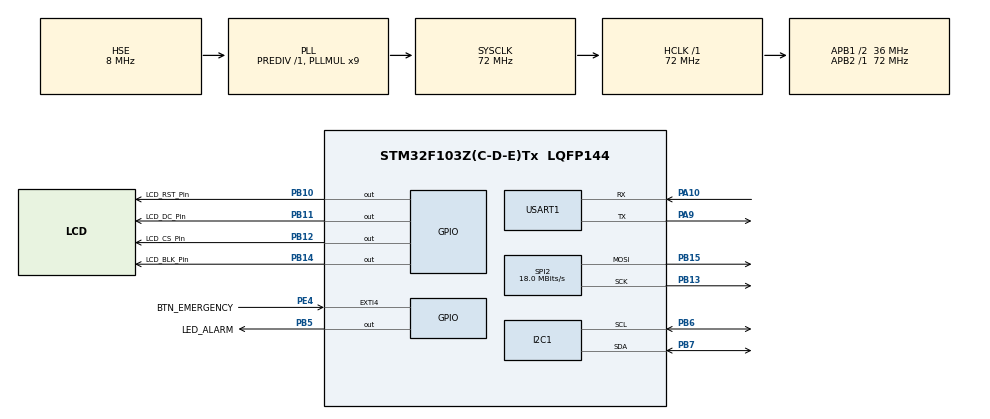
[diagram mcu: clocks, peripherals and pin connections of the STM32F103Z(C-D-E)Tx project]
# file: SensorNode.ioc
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Dma.Request0=USART1_RX
Dma.Request1=USART1_TX
Dma.USART1_RX.0.Direction=DMA_PERIPH_TO_MEMORY
Dma.USART1_RX.0.Instance=DMA1_Channel5
Dma.USART1_RX.0.MemDataAlignment=DMA_MDATAALIGN_BYTE
Dma.USART1_RX.0.MemInc=DMA_MINC_ENABLE
Dma.USART1_RX.0.Mode=DMA_CIRCULAR
Dma.USART1_RX.0.PeriphDataAlignment=DMA_PDATAALIGN_BYTE
Dma.USART1_RX.0.PeriphInc=DMA_PINC_DISABLE
Dma.USART1_RX.0.Priority=DMA_PRIORITY_MEDIUM
Dma.USART1_TX.1.Direction=DMA_MEMORY_TO_PERIPH
Dma.USART1_TX.1.Instance=DMA1_Channel4
Dma.USART1_TX.1.MemDataAlignment=DMA_MDATAALIGN_BYTE
Dma.USART1_TX.1.MemInc=DMA_MINC_ENABLE
Dma.USART1_TX.1.Mode=DMA_NORMAL
Dma.USART1_TX.1.PeriphDataAlignment=DMA_PDATAALIGN_BYTE
Dma.USART1_TX.1.PeriphInc=DMA_PINC_DISABLE
Dma.USART1_TX.1.Priority=DMA_PRIORITY_MEDIUM
Mcu.Family=STM32F1
Mcu.Name=STM32F103Z(C-D-E)Tx
Mcu.Package=LQFP144
NVIC.DMA1_Channel4_IRQn=true\:0\:0\:false\:false\:true\:false\:true\:true
NVIC.DMA1_Channel5_IRQn=true\:0\:0\:false\:false\:true\:false\:true\:true
NVIC.EXTI4_IRQn=true\:6\:0\:true\:false\:true\:true\:true\:true
NVIC.PriorityGroup=NVIC_PRIORITYGROUP_4
NVIC.TIM4_IRQn=true\:15\:0\:false\:false\:true\:false\:true\:true
NVIC.TimeBase=TIM4_IRQn
NVIC.TimeBaseIP=TIM4
NVIC.USART1_IRQn=true\:6\:0\:true\:false\:true\:true\:true\:true
OSC_IN.Mode=HSE-External-Oscillator
OSC_IN.Signal=RCC_OSC_IN
OSC_OUT.Mode=HSE-External-Oscillator
OSC_OUT.Signal=RCC_OSC_OUT
PA10.Mode=Asynchronous
PA10.Signal=USART1_RX
PA13.Mode=Serial_Wire
PA13.Signal=SYS_JTMS-SWDIO
PA14.Mode=Serial_Wire
PA14.Signal=SYS_JTCK-SWCLK
PA9.Mode=Asynchronous
PA9.Signal=USART1_TX
PB10.GPIO_Label=LCD_RST_Pin
PB10.PinState=GPIO_PIN_SET
PB10.Signal=GPIO_Output
PB11.GPIO_Label=LCD_DC_Pin
PB11.PinState=GPIO_PIN_SET
PB11.Signal=GPIO_Output
PB12.GPIO_Label=LCD_CS_Pin
PB12.PinState=GPIO_PIN_SET
PB12.Signal=GPIO_Output
PB13.Mode=TX_Only_Simplex_Unidirect_Master
PB13.Signal=SPI2_SCK
PB14.GPIO_Label=LCD_BLK_Pin
PB14.PinState=GPIO_PIN_SET
PB14.Signal=GPIO_Output
PB15.Mode=TX_Only_Simplex_Unidirect_Master
PB15.Signal=SPI2_MOSI
PB5.GPIO_Label=LED_ALARM
PB5.PinState=GPIO_PIN_SET
PB5.Signal=GPIO_Output
PB6.Mode=I2C
PB6.Signal=I2C1_SCL
PB7.Mode=I2C
PB7.Signal=I2C1_SDA
PE4.GPIO_Label=BTN_EMERGENCY
PE4.GPIO_ModeDefaultEXTI=GPIO_MODE_IT_FALLING
PE4.GPIO_PuPd=GPIO_PULLUP
PE4.Signal=GPXTI4
ProjectManager.HeapSize=0x200
ProjectManager.StackSize=0x400
ProjectManager.TargetToolchain=MDK-ARM V5.32
RCC.AHBFreq_Value=72000000
RCC.APB1CLKDivider=RCC_HCLK_DIV2
RCC.APB1Freq_Value=36000000
RCC.APB1TimFreq_Value=72000000
RCC.APB2Freq_Value=72000000
RCC.APB2TimFreq_Value=72000000
RCC.HCLKFreq_Value=72000000
RCC.PLLMUL=RCC_PLL_MUL9
RCC.PLLSourceVirtual=RCC_PLLSOURCE_HSE
RCC.SYSCLKFreq_VALUE=72000000
RCC.SYSCLKSource=RCC_SYSCLKSOURCE_PLLCLK
RCC.USBFreq_Value=72000000
SPI2.CalculateBaudRate=18.0 MBits/s
SPI2.Direction=SPI_DIRECTION_2LINES
SPI2.Mode=SPI_MODE_MASTER
SPI2.VirtualType=VM_MASTER
USART1.VirtualMode=VM_ASYNC
VP_SYS_VS_tim4.Mode=TIM4
board=custom

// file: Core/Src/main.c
/* USER CODE BEGIN Header */
/**
  ******************************************************************************
  * @file           : main.c
  * @brief          : Main program body
  ******************************************************************************
  * @attention
  *
  * Copyright (c) 2026 STMicroelectronics.
  * All rights reserved.
  *
  * This software is licensed under terms that can be found in the LICENSE file
  * in the root directory of this software component.
  * If no LICENSE file comes with this software, it is provided AS-IS.
  *
  ******************************************************************************
  */
/* USER CODE END Header */
#include "main.h"
#include "dma.h"
#include "i2c.h"
#include "spi.h"
#include "usart.h"
#include "gpio.h"

/* USER CODE BEGIN Includes */
#include "app_tasks.h"
#include "FreeRTOS.h"
#include "task.h"
/* USER CODE END Includes */

void SystemClock_Config(void);

/* USER CODE BEGIN 0 */
/* USER CODE BEGIN 0 */
// ??? Modbus CRC16 ???? (C???)

/* USER CODE END 0 */

int main(void)
{

  /* MCU Configuration--------------------------------------------------------*/

  /* Reset of all peripherals, Initializes the Flash interface and the Systick. */
  HAL_Init();

  /* Configure the system clock */
  SystemClock_Config();

  /* Initialize all configured peripherals */
  MX_GPIO_Init();
  MX_DMA_Init();
  MX_I2C1_Init();
  MX_USART1_UART_Init();
  MX_SPI2_Init();
  /* USER CODE BEGIN 2 */

  // 1. 调用业务层初始化接口，创建所有任务与队列
  AppTask_Init();

  // 2. 启动 RTOS 调度器，交出 CPU 控制权
  vTaskStartScheduler();

  /* USER CODE END 2 */

  /* Infinite loop */
  while (1)
  {

	}
}

void SystemClock_Config(void)
{
  RCC_OscInitTypeDef RCC_OscInitStruct = {0};
  RCC_ClkInitTypeDef RCC_ClkInitStruct = {0};

  /** Initializes the RCC Oscillators according to the specified parameters
  * in the RCC_OscInitTypeDef structure.
  */
  RCC_OscInitStruct.OscillatorType = RCC_OSCILLATORTYPE_HSE;
  RCC_OscInitStruct.HSEState = RCC_HSE_ON;
  RCC_OscInitStruct.HSEPredivValue = RCC_HSE_PREDIV_DIV1;
  RCC_OscInitStruct.HSIState = RCC_HSI_ON;
  RCC_OscInitStruct.PLL.PLLState = RCC_PLL_ON;
  RCC_OscInitStruct.PLL.PLLSource = RCC_PLLSOURCE_HSE;
  RCC_OscInitStruct.PLL.PLLMUL = RCC_PLL_MUL9;
  if (HAL_RCC_OscConfig(&RCC_OscInitStruct) != HAL_OK)
  {
    Error_Handler();
  }

  /** Initializes the CPU, AHB and APB buses clocks
  */
  RCC_ClkInitStruct.ClockType = RCC_CLOCKTYPE_HCLK|RCC_CLOCKTYPE_SYSCLK
                              |RCC_CLOCKTYPE_PCLK1|RCC_CLOCKTYPE_PCLK2;
  RCC_ClkInitStruct.SYSCLKSource = RCC_SYSCLKSOURCE_PLLCLK;
  RCC_ClkInitStruct.AHBCLKDivider = RCC_SYSCLK_DIV1;
  RCC_ClkInitStruct.APB1CLKDivider = RCC_HCLK_DIV2;
  RCC_ClkInitStruct.APB2CLKDivider = RCC_HCLK_DIV1;

  if (HAL_RCC_ClockConfig(&RCC_ClkInitStruct, FLASH_LATENCY_2) != HAL_OK)
  {
    Error_Handler();
  }
}

void HAL_TIM_PeriodElapsedCallback(TIM_HandleTypeDef *htim)
{
  if (htim->Instance == TIM4)
  {
    HAL_IncTick();
  }
}

void Error_Handler(void)
{
  __disable_irq();
  while (1)
  {
  }
}
